# PIC32MX664F128L device description
Architecture: MIPS; Family: PIC32MX; Series: PIC32MX
Registers are 32-bit, read-write, no defined reset value unless marked. A register's access mark holds for its fields unless they carry their own. Offsets are from the block's base; [hi:lo] are bit positions; {n}, {i} and the like mark numbered series; 'fields as' and 'values as' point back to an identical list.

## CORE
Instances: CORE 0x0
0x00 zero ro
0x04 at
0x08 v0
0x0C v1
{0x10+4i} a{i} (i=0..3)
{0x20+4i} t{i} (i=0..7)
{0x40+4i} s{i} (i=0..7)
0x60 t8
0x64 t9
0x68 k0
0x6C k1
0x70 gp
0x74 sp
0x78 fp
0x7C ra
0x80 HWREna
  [3:0] Mask
0x84 BadVAddr ro
0x88 Count
0x8C Compare
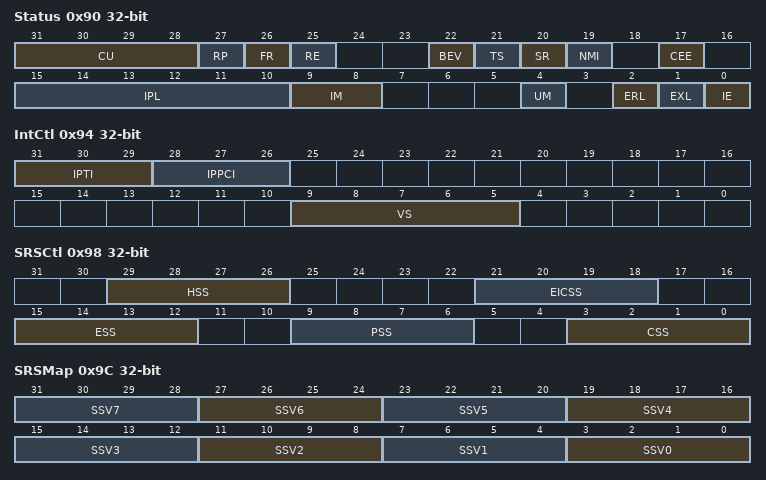
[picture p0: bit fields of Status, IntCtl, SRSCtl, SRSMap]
0x90 Status
  [31:28] CU, [27] RP, [26] FR, [25] RE, [22] BEV, [21] TS, [20] SR, [19] NMI, [17] CEE, [15:10] IPL, [9:8] IM, [4] UM, [2] ERL, [1] EXL, [0] IE
0x94 IntCtl
  [31:29] IPTI, [28:26] IPPCI, [9:5] VS
0x98 SRSCtl
  [29:26] HSS, [21:18] EICSS, [15:12] ESS, [9:6] PSS, [3:0] CSS
0x9C SRSMap
  [4n+3:4n] SSV{n} (n=0..7)
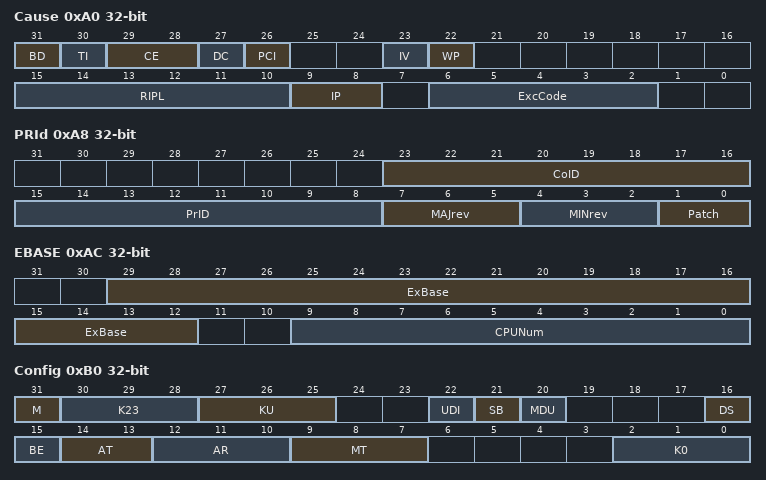
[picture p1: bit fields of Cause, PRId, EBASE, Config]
0xA0 Cause
  [31] BD, [30] TI, [29:28] CE, [27] DC, [26] PCI, [23] IV, [22] WP, [15:10] RIPL, [9:8] IP, [6:2] ExcCode
0xA4 EPC
0xA8 PRId ro
  [23:16] CoID, [15:8] PrID, [7:5] MAJrev, [4:2] MINrev, [1:0] Patch
0xAC EBASE
  [29:12] ExBase, [9:0] CPUNum
0xB0 Config
  [31] M, [30:28] K23, [27:25] KU, [22] UDI, [21] SB, [20] MDU, [16] DS, [15] BE, [14:13] AT, [12:10] AR, [9:7] MT, [2:0] K0
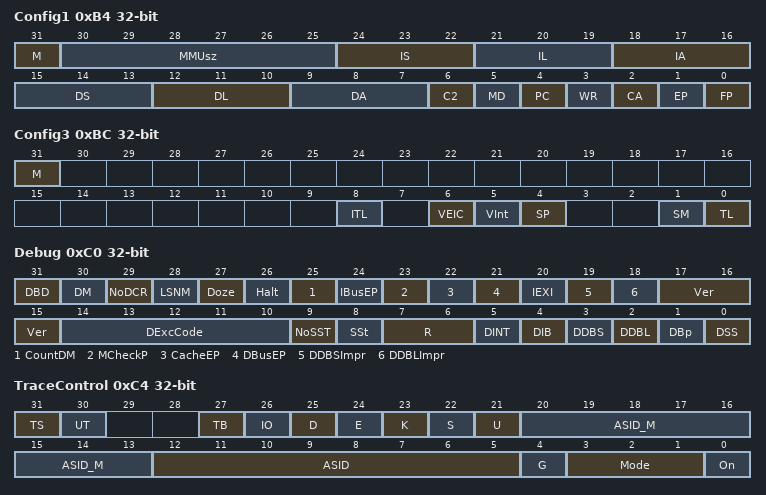
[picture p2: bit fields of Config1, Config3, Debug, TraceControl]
0xB4 Config1 ro
  [31] M, [30:25] MMUsz, [24:22] IS, [21:19] IL, [18:16] IA, [15:13] DS, [12:10] DL, [9:7] DA, [6] C2, [5] MD, [4] PC, [3] WR, [2] CA, [1] EP, [0] FP
0xB8 Config2 ro
  [31] M
0xBC Config3 ro
  [31] M, [8] ITL, [6] VEIC, [5] VInt, [4] SP, [1] SM, [0] TL
0xC0 Debug
  [31] DBD, [30] DM, [29] NoDCR, [28] LSNM, [27] Doze, [26] Halt, [25] CountDM, [24] IBusEP, [23] MCheckP, [22] CacheEP, [21] DBusEP, [20] IEXI, [19] DDBSImpr, [18] DDBLImpr, [17:15] Ver, [14:10] DExcCode, [9] NoSST, [8] SSt, [7:6] R, [5] DINT, [4] DIB, [3] DDBS, [2] DDBL, [1] DBp, [0] DSS
0xC4 TraceControl
  [31] TS, [30] UT, [27] TB, [26] IO, [25] D, [24] E, [23] K, [22] S, [21] U, [20:13] ASID_M, [12:5] ASID, [4] G, [3:1] Mode, [0] On
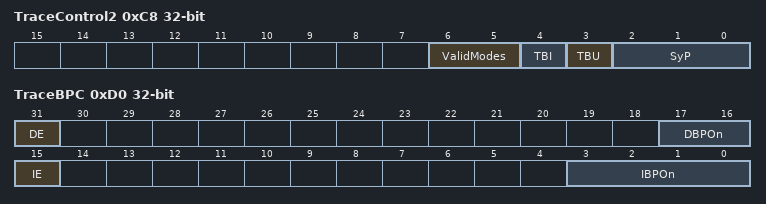
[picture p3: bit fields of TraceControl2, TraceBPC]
0xC8 TraceControl2 ro
  [6:5] ValidModes, [4] TBI, [3] TBU, [2:0] SyP
0xCC UserTraceData
  [31:0] Data
0xD0 TraceBPC
  [31] DE, [17:16] DBPOn, [15] IE, [3:0] IBPOn
0xD4 Debug2
0xD8 DEPC
0xDC ErrorEPC
0xE0 DESAVE
0xE4 lo
  [31:0] MDUlow
0xE8 hi
  [31:0] MDUhigh

## CVR
Instances: CVR 0x1f8097f4 in periph0
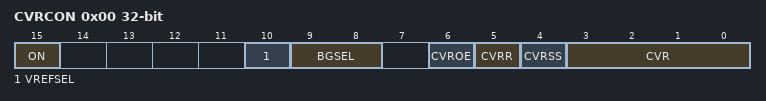
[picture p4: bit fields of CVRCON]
0x00 CVRCON — Comparator Voltage Reference Control Register
  [15] ON — Comparator Voltage Reference On bit
    1=Module is enabled. Setting this bit does not affect other bits in the register.; 0=Module is disabled and does not consume current. Clearing this bit does not affect the other bits in the register.
  [10] VREFSEL — Voltage Reference Select bit
    1=CVREF = VREF+; 0=CVREF is generated by the resistor network
  [9:8] BGSEL — Band Gap Reference Source bits
    3=IVREF = VREF+; 1=IVREF = 0.6V (nominal, default); 0=IVREF = 1.2V (nominal)
  [6] CVROE — CVrefout Enable bit
    1=Voltage level is output on CVrefout pin; 0=Voltage level is disconnected from CVrefout pin
  [5] CVRR — CVref Range Selection bit
    1=0 to 0.67 CVrsrc with CVrsrc/24 step size; 0=0.25 CVrsrc to 0.75 CVrsrc with CVrsrc/32 step size
  [4] CVRSS — CVref Source Selection bit
    1=Comparator voltage reference source CVrsrc = (Vref+) - (Vref-); 0=Comparator voltage reference source CVrsrc = AVdd - AVss
  [3:0] CVR — CVref Value Selection
    {v}=(When CVRR is 1) CVREF is ({v}/24) * CVRSRC / (When CVRR is 0) CVREF is ({v+8}/32)*CVRSRC (v=0..15)

## DDPSTAT
Instances: DDPSTAT 0x1f880140 in periph2
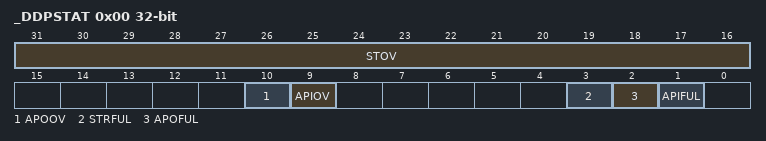
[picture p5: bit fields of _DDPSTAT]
0x00 _DDPSTAT
  [31:16] STOV, [10] APOOV, [9] APIOV, [3] STRFUL, [2] APOFUL, [1] APIFUL
0x30 _STRO — George
0x40 _APPO — George
0x50 _APPI — George

## ICAP
Instances: ICAP 0x1f801ff4 in periph0
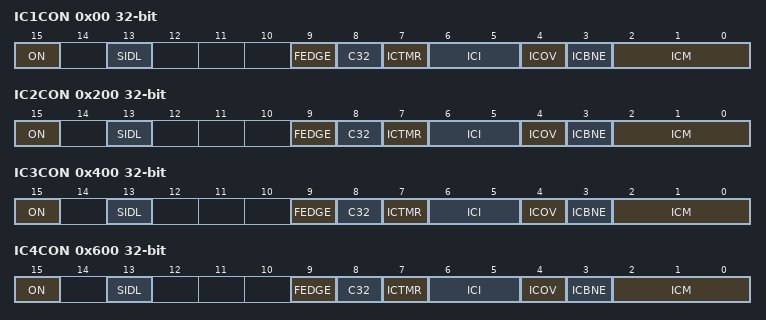
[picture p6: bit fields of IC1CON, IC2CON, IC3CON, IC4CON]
0x00 IC1CON — Input Capture 1 Control Register
  [15] ON — Input Capture Module Enable bit
    1=Module is enabled; 0=Disable and reset module, disable clocks, disable interrupt generation and allow SFR modifications
  [13] SIDL — Stop in Idle Control bit
    1=Halt in Idle mode; 0=Continue to operate in Idle mode
  [9] FEDGE — First Capture Edge Select bit
    1=Capture rising edge first; 0=Capture falling edge first
  [8] C32 — 32-bit Capture Select bit
    1=32-bit timer resource capture; 0=16-bit timer resource capture
  [7] ICTMR — Timer Select bit
    0=Timer3 is the counter source for capture; 1=Timer2 is the counter source for capture
  [6:5] ICI — Interrupt Control bits
    3=Interrupt on every fourth capture event; 2=Interrupt on every third capture event; 1=Interrupt on every second capture event; 0=Interrupt on every capture event
  [4] ICOV — Input Capture Overflow Status Flag bit (read-only)
    1=Input capture overflow has occurred; 0=No input capture overflow has occurred
  [3] ICBNE — Input Capture Buffer Not Empty Status bit (read-only)
    1=Input capture buffer is not empty; at least one more capture value can be read; 0=Input capture buffer is empty
  [2:0] ICM — Input Capture Mode Select bits
    7=Interrupt-Only mode (only supported while in Sleep mode or Idle mode); 6=Simple Capture Event mode every edge, specified edge first and every edge thereafter; 5=Prescaled Capture Event mode every sixteenth rising edge; 4=Prescaled Capture Event mode every fourth rising edge; 3=Simple Capture Event mode every rising edge; 2=Simple Capture Event mode every falling edge; 1=Edge Detect mode every edge (rising and falling); 0=Input Capture module is disabled
0x10 IC1BUF ro
0x200 IC2CON — Input Capture 1 Control Register
  fields as IC1CON
0x210 IC2BUF ro
0x400 IC3CON — Input Capture 1 Control Register
  fields as IC1CON
0x410 IC3BUF ro
0x600 IC4CON — Input Capture 1 Control Register
  fields as IC1CON
0x610 IC4BUF ro
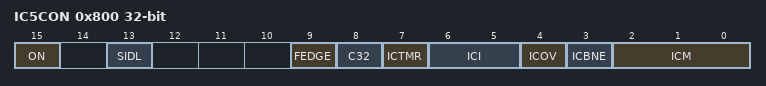
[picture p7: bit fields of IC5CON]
0x800 IC5CON — Input Capture 1 Control Register
  fields as IC1CON
0x810 IC5BUF ro

## Notices in the file
Copyright (c) 2019 Microchip Technology Inc.
SPDX-License-Identifier: Apache-2.0
Licensed under the Apache License, Version 2.0 (the "License");
you may not use this file except in compliance with the License.
You may obtain a copy of the License at
http://www.apache.org/licenses/LICENSE-2.0
Unless required by applicable law or agreed to in writing, software
distributed under the License is distributed on an "AS IS" BASIS,
WITHOUT WARRANTIES OR CONDITIONS OF ANY KIND, either express or implied.
See the License for the specific language governing permissions and
limitations under the License.
